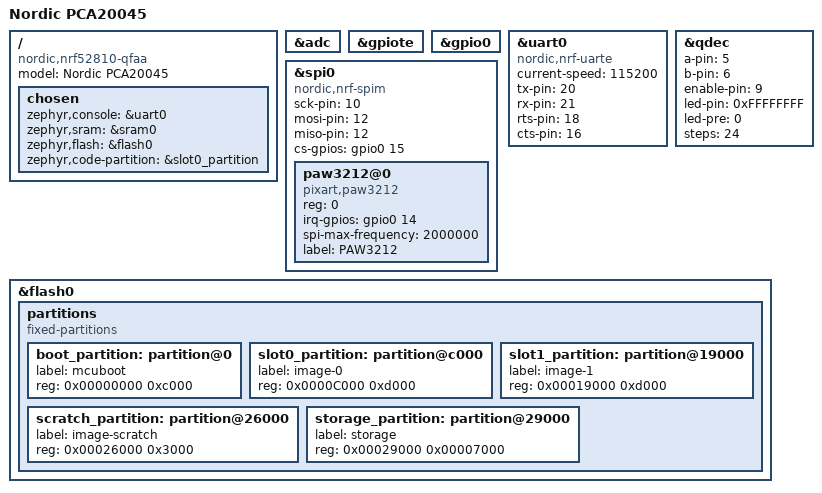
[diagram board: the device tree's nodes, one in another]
/*
 * Copyright (c) 2019 Nordic Semiconductor ASA
 *
 * SPDX-License-Identifier: LicenseRef-BSD-5-Clause-Nordic
 */

/dts-v1/;
#include <nordic/nrf52810_qfaa.dtsi>

/ {
	model = "Nordic PCA20045";
	compatible = "nordic,nrf52810-qfaa",
		     "nordic,nrf52810";

	chosen {
		zephyr,console = &uart0;
		zephyr,sram = &sram0;
		zephyr,flash = &flash0;
		zephyr,code-partition = &slot0_partition;
	};
};

&adc {
	status = "okay";
};

&gpiote {
	status = "okay";
};

&gpio0 {
	status = "okay";
};

&uart0 {
	status = "okay";
	compatible = "nordic,nrf-uarte";
	current-speed = <115200>;
	tx-pin = <20>;
	rx-pin = <21>;
	rts-pin = <18>;
	cts-pin = <16>;
};

&qdec {
	status = "okay";
	a-pin = <5>;
	b-pin = <6>;
	enable-pin = <9>;
	led-pin = <0xFFFFFFFF>;
	led-pre = <0>;
	steps = <24>;
};

&spi0 {
	compatible = "nordic,nrf-spim";
	status = "okay";
	sck-pin = <10>;
	mosi-pin = <12>;
	miso-pin = <12>;
	cs-gpios = <&gpio0 15 0>;

	paw3212@0 {
		compatible = "pixart,paw3212";
		reg = <0>;
		irq-gpios = <&gpio0 14 0>;
		spi-max-frequency = <2000000>;
		label = "PAW3212";
	};
};

&flash0 {
	/*
	 * For more information, see:
	 * http://docs.zephyrproject.org/latest/guides/dts/index.html#flash-partitions
	 */
	partitions {
		compatible = "fixed-partitions";
		#address-cells = <1>;
		#size-cells = <1>;

		boot_partition: partition@0 {
			label = "mcuboot";
			reg = <0x00000000 0xc000>;
		};
		slot0_partition: partition@c000 {
			label = "image-0";
			reg = <0x0000C000 0xd000>;
		};
		slot1_partition: partition@19000 {
			label = "image-1";
			reg = <0x00019000 0xd000>;
		};
		scratch_partition: partition@26000 {
			label = "image-scratch";
			reg = <0x00026000 0x3000>;
		};
		storage_partition: partition@29000 {
			label = "storage";
			reg = <0x00029000 0x00007000>;
		};
	};
};
